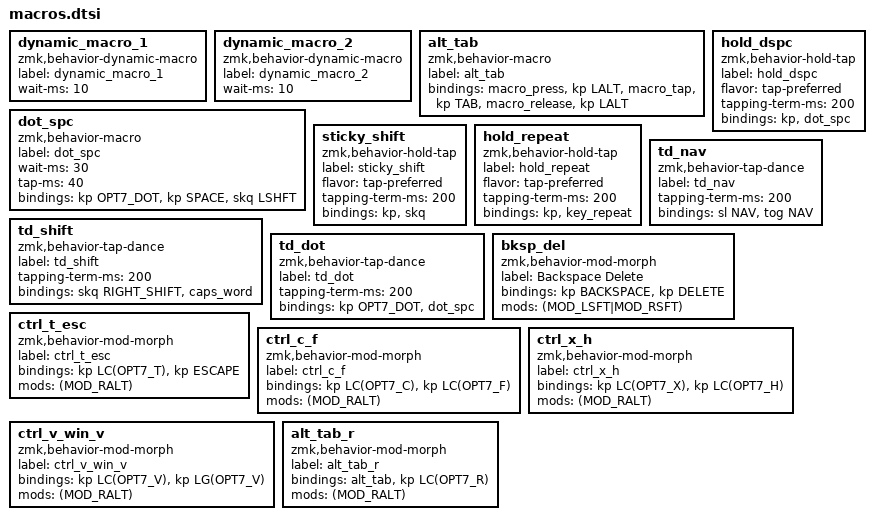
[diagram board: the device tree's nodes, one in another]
// Macros dynamiques

dynamic_macro_1: dynamic_macro_1 {
	compatible = "zmk,behavior-dynamic-macro";
	label = "dynamic_macro_1";
	wait-ms = <10>;
	#binding-cells = <1>;
};

dynamic_macro_2: dynamic_macro_2 {
	compatible = "zmk,behavior-dynamic-macro";
	label = "dynamic_macro_2";
	wait-ms = <10>;
	#binding-cells = <1>;
};





// Raccourcis

alt_tab: alt_tab {
	compatible = "zmk,behavior-macro";
	label = "alt_tab";
	#binding-cells = <0>;
	bindings
		= <&macro_press &kp LALT>
		, <&macro_tap &kp TAB>
		, <&macro_release &kp LALT>
	;
};

//  dot -> space -> sticky shift
dot_spc: dot_spc {
	compatible = "zmk,behavior-macro";
	label = "dot_spc";
	wait-ms = <30>;
	tap-ms = <40>;
	#binding-cells = <0>;
	bindings = <&kp OPT7_DOT &kp SPACE &skq LSHFT>;
};





// Tap hold

hold_dspc: hold_dspc {
	compatible = "zmk,behavior-hold-tap";
	label = "hold_dspc";
	#binding-cells = <2>;
	flavor = "tap-preferred";
	tapping-term-ms = <200>;
	bindings = <&kp>, <&dot_spc>;
};

sticky_shift: sticky_shift {
	compatible = "zmk,behavior-hold-tap";
	label = "sticky_shift";
	#binding-cells = <2>;
	flavor = "tap-preferred";
	tapping-term-ms = <200>;
	bindings = <&kp>, <&skq>;
};

hold_repeat: hold_repeat {
	compatible = "zmk,behavior-hold-tap";
	label = "hold_repeat";
	#binding-cells = <2>;
	flavor = "tap-preferred";
	tapping-term-ms = <200>;
	bindings = <&kp>, <&key_repeat>;
};




// Tap dance

td_nav: td_nav {
	compatible = "zmk,behavior-tap-dance";
	label = "td_nav";
	#binding-cells = <0>;
	tapping-term-ms = <200>;
	bindings = <&sl NAV>, <&tog NAV>;
};

td_shift: td_shift {
	compatible = "zmk,behavior-tap-dance";
	label = "td_shift";
	#binding-cells = <0>;
	tapping-term-ms = <200>;
	bindings = <&skq RIGHT_SHIFT>, <&caps_word>;
};

td_dot: td_dot {
	compatible = "zmk,behavior-tap-dance";
	label = "td_dot";
	#binding-cells = <0>;
	tapping-term-ms = <200>;
	bindings = <&kp OPT7_DOT>, <&dot_spc>;
};





// Mod morph

bksp_del: bksp_del {
	compatible = "zmk,behavior-mod-morph";
	label = "Backspace Delete";
	#binding-cells = <0>;
	bindings = <&kp BACKSPACE>, <&kp DELETE>;
	mods = <(MOD_LSFT|MOD_RSFT)>;
};





// Non utilisés

ctrl_t_esc: ctrl_t_esc {
	compatible = "zmk,behavior-mod-morph";
	label = "ctrl_t_esc";
	#binding-cells = <0>;
	bindings = <&kp LC(OPT7_T)>, <&kp ESCAPE>;
	mods = <(MOD_RALT)>;
};

ctrl_c_f: ctrl_c_f {
	compatible = "zmk,behavior-mod-morph";
	label = "ctrl_c_f";
	#binding-cells = <0>;
	bindings = <&kp LC(OPT7_C)>, <&kp LC(OPT7_F)>;
	mods = <(MOD_RALT)>;
};

ctrl_x_h: ctrl_x_h {
	compatible = "zmk,behavior-mod-morph";
	label = "ctrl_x_h";
	#binding-cells = <0>;
	bindings = <&kp LC(OPT7_X)>, <&kp LC(OPT7_H)>;
	mods = <(MOD_RALT)>;
};

ctrl_v_win_v: ctrl_v_win_v {
	compatible = "zmk,behavior-mod-morph";
	label = "ctrl_v_win_v";
	#binding-cells = <0>;
	bindings = <&kp LC(OPT7_V)>, <&kp LG(OPT7_V)>;
	mods = <(MOD_RALT)>;
};

alt_tab_r: alt_tab_r {
	compatible = "zmk,behavior-mod-morph";
	label = "alt_tab_r";
	#binding-cells = <0>;
	bindings = <&alt_tab>, <&kp LC(OPT7_R)>;
	mods = <(MOD_RALT)>;
};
